# SDFM_SDFM_50268000h register map
Vendor: Texas Instruments
Peripheral module from a debugger description file (folder AM263P).
Registers are 16-bit, read-write, reset 0x0 unless marked. A register's access mark holds for its fields unless they carry their own. Offsets are as the file gives them; lines under a group give offsets from that group; [hi:lo] are bit positions; {n}, {i} and the like mark numbered series; 'fields as' and 'values as' point back to an identical list; <NAME> marks a mode.

## SDFM
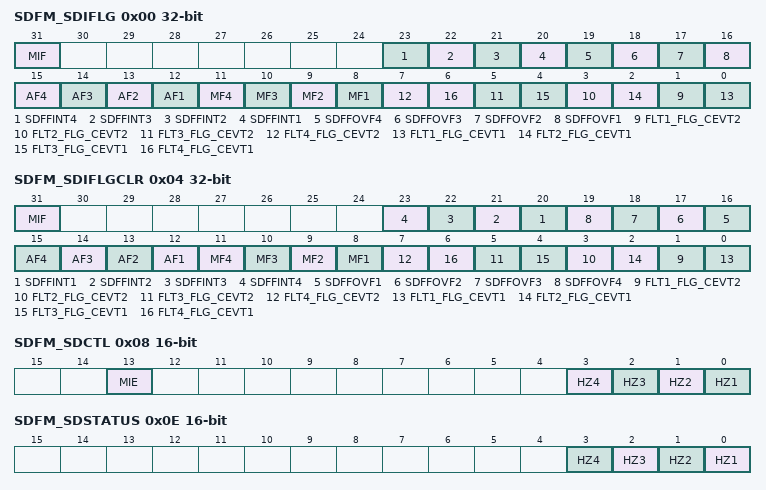
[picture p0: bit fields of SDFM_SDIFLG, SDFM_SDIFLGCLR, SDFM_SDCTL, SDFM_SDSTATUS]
0x00 SDFM_SDIFLG 32-bit ro — SD Interrupt Flag Register.
  [31] MIF — Set whenever any 'error' interrupt [MF1-4,IFL1-4,IFH1-4,SDFFOVF1-4] is active
  [23] SDFFINT4 — SDFIFO data ready interrupt for Ch4
  [22] SDFFINT3 — SDFIFO data ready interrupt for Ch3
  [21] SDFFINT2 — SDFIFO data ready interrupt for Ch2
  [20] SDFFINT1 — SDFIFO data ready interrupt for Ch1 0: SDFIFO data ready interrupt has NOT occurred 1: SDFIFO data ready interrupt has occurred
  [19] SDFFOVF4 — FIFO Overflow Flag for Ch4
  [18] SDFFOVF3 — FIFO Overflow Flag for Ch3
  [17] SDFFOVF2 — FIFO Overflow Flag for Ch2
  [16] SDFFOVF1 — FIFO Overflow Flag for Ch1 0 - FIFO has not overflowed 1 - FIFO overflowed. # words received in FIFO ' FIFO depth [16], NEW word is lost
  [n+11] AF{n} (n=1..4) — Acknowledge flag for Filter {n} 0:No new data available for Filter [in non-FIFO mode] 1:New data available for Filter [in non-FIFO mode]
  [n+7] MF{n} (n=1..4) — Modulator Failure for Filter {n} 0:Modulator is operating normally for Filter 1:Modulator failure for Filter
  [2n-1] FLT{n}_FLG_CEVT2 (n=1..4) — CEVT2 Interrupt flag for filter{n} 0:CEVT2 event has not occured 1:CEVT2 event has occurred
  [2n-2] FLT{n}_FLG_CEVT1 (n=1..4) — CEVT1 Interrupt flag for filter{n} 0:CEVT1 event has not occured 1:CEVT1 event has occurred
0x04 SDFM_SDIFLGCLR 32-bit access not given — SD Module Interrupt Flag Clear Bits: Writing a '1' will clear the respective flag bit in the SDIFLG register. Writes of '0' are ignored. Note: If user writes a '1' to clear a bit on the same cycle that the hardware is trying to set the bit to '1', then hardware has priority and the bit will not be cleared.
  [31] MIF — Flag-clear bit for SDFM Master Interrupt flag. Writing a 1 to clear MIF flag in SDIFLG register Writes of '0' are ignored. Note: If the MIF flag is cleared and other Interrupts are still pending, MIF will again be set to 1 on the following SysClk cycle, and the INT output will be reasserted [pulsed low] (access R/W1TS)
  [n+19] SDFFINT{n} (n=1..4) — SDFIFO data ready Interrupt flag-clear bit for Ch{n} (access R/W1TS)
  [n+15] SDFFOVF{n} (n=1..4) — SDFIFO overflow clear Ch{n} (access R/W1TS)
  [15] AF4 — Flag-clear bit for Acknowledge flag for Filter 4 (access R/W1TS)
  [14] AF3 — Flag Clear bit for AF3 (access R/W1TS)
  [13] AF2 — Flag Clear bit for AF2 (access R/W1TS)
  [12] AF1 — Flag Clear bit for AF1 (access R/W1TS)
  [n+7] MF{n} (n=1..4) — Flag Clear bit for MF{n} (access R/W1TS)
  [2n-1] FLT{n}_FLG_CEVT2 (n=1..4) — Flag Clear bit for FLT{n}_FLG_CEVT2 (access R/W1TS)
  [2n-2] FLT{n}_FLG_CEVT1 (n=1..4) — Flag Clear bit for FLT{n}_FLG_CEVT1 (access R/W1TS)
0x08 SDFM_SDCTL access not given — SD Control Register.
  [13] MIE rw — Master SDy_ERR interrupt enable 0:SDy_ERR Interrupt and interrupt flags are disabled 1:SDy_ERR Interrupt and interrupt flags are enabled
  [n-1] HZ{n} (n=1..4) — Flag Clear bit for HZ{n} (access R/W1TS)
0x0C SDFM_SDMFILEN — SD Master Filter Enable.
  [11] MFE — Master Filter Enable 0:All the four data filter units of SDFM module are disabled. All FIFOs are cleared 1:Data filter units can be enabled if bit FEN is '1'.
0x0E SDFM_SDSTATUS ro — SD Status Register.
  [n-1] HZ{n} (n=1..4) — High-level Threshold crossing [Z] flag Ch{n} Primarily intended for detecting 'zero'-crossing events. Unlike the primary comparator IFHx flag, it does not have the ability to generate an interrupt. 0:Comparator filter output ' SDCMPHZ{n}.HLTZ 1:Comparator filter output '= SDCMPHZ{n}.HLTZ
0x10 SDFM_SDINTMODE — SD Interrupt Mode register.
  [0] SDINTMODESEL — CompxH/L events interrupt mode select 0 CompxH/L events are treated as edge signals, rise-edge detect will be done to qualify the event for interrupt generation 1 CompxH/L events are treated as level signals. Rise-edge detect will not be performed and interrupt will be re-asserted if the event remains asserted.
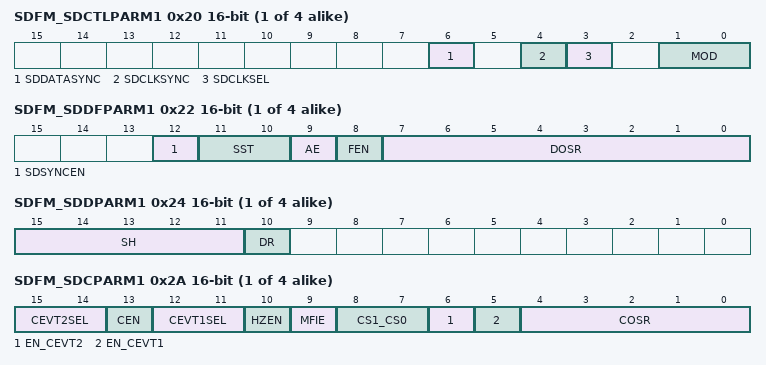
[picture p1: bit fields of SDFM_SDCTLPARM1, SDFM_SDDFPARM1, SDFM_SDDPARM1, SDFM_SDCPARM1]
{0x0+0x20*i} SDFM_SDCTLPARM{i} (i=1..4) — Control Parameter Register for Ch{i}.
  [6] SDDATASYNC — 0: SD Data is not passed through a synchronizer. 1:SD Data is passed through a synchronizer.
  [4] SDCLKSYNC — 0: SD Clock is not passed through a synchronizer. 1:SD Clock is passed through a synchronizer.
  [3] SDCLKSEL — SD{i} Clock source select. 0:Clock source to SDFM filter is its channel clock. 1:Clock source to SDFM filter is SD1 filter clock.
  [1:0] MOD — Modulator clock modes 0:Mode0:Modulator clock running at 1x data rate 1:Reserved 2:Reserved 3:Reserved
{0x2+0x20*i} SDFM_SDDFPARM{i} (i=1..4) — Data Filter Parameter Register for Ch{i}.
  [12] SDSYNCEN — PWM synchronization [SDSYNC] of data filter 0:PWM synchronization of data filter is disabled 1:PWM synchronization of data filter is enabled Note: SDSYNCx.SYNCSEL bits define which PWM signal is used to synchronize PWMs
  [11:10] SST — Data filter structure 00:Data filter runs with a Sincfast structure 01:Data filter runs with a Sinc1 structure 10:Data filter runs with a Sinc2 structure 11:Data filter runs with a Sinc3 structure
  [9] AE — Data filter Acknowledge Enable 0:Acknowledge flag is disabled for the particular filter 1:Acknowledge flag is enabled for the particular filter
  [8] FEN — Filter Enable 0: The data filter is disabled and no data is produced 1: The data filter is enabled and data are produced in the data filter Note: When filter is disabled, DOSR counter held in reset, filter data erased. Also resets FIFO pointers and clears the FIFO
  [7:0] DOSR — Data filter Oversampling ratio The actual oversampling ratio of data filter is DOSR + 1 These bits set the oversampling ratio of the data filter. 0x0FF represents an oversampling ratio of 256.
{0x4+0x20*i} SDFM_SDDPARM{i} (i=1..4) — Data Parameter Register for Ch{i}.
  [15:11] SH — Shift Control These bits indicate by how many bits the 16-bit window is shifted up when 16-bit data representation is chosen.
  [10] DR — Data filter Data representation 0:Data stored in16b2's complement 1:Data stored in32b2's complement
{0x6+0x20*i} SDFM_SDFLT{i}CMPH1 reset 0x7FFF (i=1..4) — High-level Threshold Register for Ch{i}.
  [14:0] HLT — Unsigned high-level threshold for the comparator filter output.
{0x8+0x20*i} SDFM_SDFLT{i}CMPL1 (i=1..4) — Low-level Threshold Register for Ch{i}.
  [14:0] LLT — Unsigned low-level threshold for the comparator filter output.
{0xA+0x20*i} SDFM_SDCPARM{i} (i=1..4) — Comparator Filter Parameter Register for Ch{i}.
  [15:14] CEVT2SEL — Comparator Event2 Select 00: COMPL1 01:COMPL1 OR COMPH1 10:COMPL2 11:COMPL2 OR COMPH2
  [13] CEN — Comparator Filter enable 0:Disable comparator filter 1:Enable comparator filter
  [12:11] CEVT1SEL — Comparator Event1 Select 00: COMPH1 01:COMPL1 OR COMPH1 10:COMPH2 11:COMPL2 OR COMPH2
  [10] HZEN — High level [Z] Threshold crossing output enable 0:Disable Higher level Threshold [Z] crossing 1:Enable Higher level Threhold [Z] crossing
  [9] MFIE — Modulator Failure Interrupt Enable 0:Disable modulator failure interrupt and its flag 1:Enable modulator failure interrupt and its flag
  [8:7] CS1_CS0 — Comparator filter structure 00:Comparator filter runs with a sincfast structure 01:Comparator filter runs with a Sinc1 structure 10:Comparator filter runs with a Sinc2 structure 11:Comparator filter runs with a Sinc3 structure
  [6] EN_CEVT2 — CEVT2 interrupt enable 0:Disable CEVT2 interrupt 1:Enable CEVT2 interrupt
  [5] EN_CEVT1 — CEVT1 interrupt enable 0:Disable CEVT1 interrupt 1:Enable CEVT1 interrupt
  [4:0] COSR — Comparator Oversampling ratio. The actual rate is COSR + 1. These bits set the oversampling ratio of the filter. 0x1F represents an oversampling ratio of 32
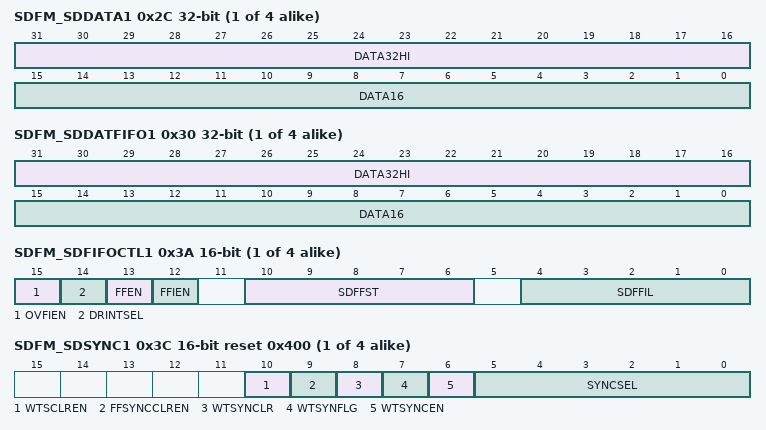
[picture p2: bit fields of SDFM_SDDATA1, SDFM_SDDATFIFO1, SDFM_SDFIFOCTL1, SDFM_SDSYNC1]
{0xC+0x20*i} SDFM_SDDATA{i} 32-bit ro (i=1..4) — Data Filter Data Register (16 or 32bit) for Ch{i}.
  [31:16] DATA32HI — Hi-order16bin32bmode, 16-bit Data in16bmode
  [15:0] DATA16 — Lo-order16bin32bmode
{0x10+0x20*i} SDFM_SDDATFIFO{i} 32-bit ro (i=1..4) — Filter Data FIFO Output(32b) for Ch{i}.
  fields as SDFM_SDDATA1
{0x14+0x20*i} SDFM_SDCDATA{i} ro (i=1..4) — Comparator Filter Data Register (16b) for Ch{i}.
  [15:0] DATA16 — Comparator Data output -16bonly
{0x16+0x20*i} SDFM_SDFLT{i}CMPH2 reset 0x7FFF (i=1..4) — Second high level threhold for CH{i}.
  [14:0] HLT2 — Second Unsigned high-level threshold for the comparator filter output.
{0x18+0x20*i} SDFM_SDFLT{i}CMPHZ (i=1..4) — High-level (Z) Threshold Register for Ch{i}.
  [14:0] HLTZ — Unsigned High-level threshold [Z] for the comparator filter output Primarily intended for detecting 'zero'-crossing events. Unlike the primary comparator SDCMPHx, it does not have the ability to generate an interrupt.
{0x1A+0x20*i} SDFM_SDFIFOCTL{i} access per field (i=1..4) — FIFO Control Register for Ch{i}.
  [15] OVFIEN rw — SDFIFO Overflow interrupt enable 0:SDFIFO Overflow condition will not generate an interrupt 1:SDFIFO overflow condition generates an interrupt on SDy_ERR
  [14] DRINTSEL rw — Data-Ready Interrupt [DRINT] source select 0 = AF1 [Select non-FIFO data-ready interrupt] 1 = SDFFINT1 [Select FIFO data-ready interrupt]
  [13] FFEN rw — SDFIFO Enable 0: Disable FIFO operation 1: Enable FIFO operation Note: When FIFO is disabled, FIFO contents are cleared
  [12] FFIEN rw — SDFIFO data ready Interrupt Enable
  [10:6] SDFFST ro — SDFIFO Status 00000 FIFO empty 00001 FIFO has 1 word . . . . 10000 FIFO has 16 words
  [4:0] SDFFIL rw — SDFIFO interrupt level bits The FIFO will generate an interrupt when the FIFO status [SDFFST] '= FIFO level [SDFFIL ]
{0x1C+0x20*i} SDFM_SDSYNC{i} access per field reset 0x400 (i=1..4) — SD Filter Sync control for Ch{i}.
  [10] WTSCLREN rw — WTSYNFLG Clear-on-FIFOINT Enable 0:WTSYNFLG can only be cleared manually [using WTSYNCLR bit] 1:WTSYNFLG is cleared automatically on SDFFINT
  [9] FFSYNCCLREN rw — FIFO Clear-on-SDSYNC Enable 0:SDFIFO is not automaticaly cleared upon receiving SDSYNC 1:SDFIFO is automaticaly cleared upon receiving SDSYNC
  [8] WTSYNCLR rw — Wait-for-Sync Flag Clear [always reads 0] 0:Write of 0 has no effect 1:Write of 1 clears WTSYNFLG
  [7] WTSYNFLG ro — Wait-for-Sync Flag 0:SDSYNC event has not occurred 1:SDSYNC event occurred.
  [6] WTSYNCEN rw — Wait-for-Sync Enable 0:Incoming Data written to SDFIFO on every Data-Ready [DR] Event 1:Incoming Data written to SDFIFO on DR event only after SDSYNC event occurs
  [5:0] SYNCSEL rw — Defines source for the SDSYNC Input on this channel Refer SDSYNCx.SYNCSEL table
{0x1E+0x20*i} SDFM_SDFLT{i}CMPL2 (i=1..4) — Second low level threhold for CH{i}.
  [14:0] LLT2 — Second Unsigned low-level threshold for the comparator filter output.
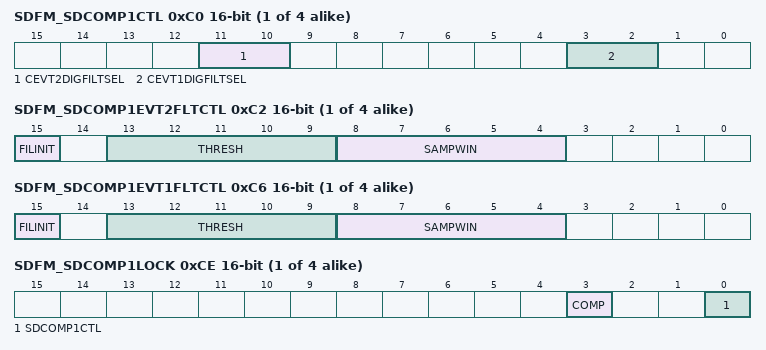
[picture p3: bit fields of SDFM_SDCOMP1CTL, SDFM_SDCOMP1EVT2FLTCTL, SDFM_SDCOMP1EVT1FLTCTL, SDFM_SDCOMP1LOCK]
{0xB0+0x10*i} SDFM_SDCOMP{i}CTL (i=1..4) — SD Comparator event filter{i} Control Register.
  [11:10] CEVT2DIGFILTSEL — High comparator COMPH source select. 0 CEVT2 output drives COMPLOUT 1 Reserved 2 Output of digital filter drives COMPLOUT 3 Reserved
  [3:2] CEVT1DIGFILTSEL — High comparator COMPH source select. 0 CEVT1 output drives COMPHOUT 1 Reserved 2 Output of digital filter drives COMPHOUT 3 Reserved
{0xB2+0x10*i} SDFM_SDCOMP{i}EVT2FLTCTL access not given (i=1..4) — COMPL/CEVT2 Digital filter{i} Control Register.
  [15] FILINIT — Low filter initialization. 0 No effect 1 Initialize all samples to the filter input value (access R/W1TS)
  [13:9] THRESH rw — Low filter majority voting threshold. At least THRESH samples of the opposite state must appear within the sample window in order for the output to change state.
  [8:4] SAMPWIN rw — Low filter sample window size. Number of samples to monitor is SAMPWIN+1.
{0xB4+0x10*i} SDFM_SDCOMP{i}EVT2FLTCLKCTL (i=1..4) — COMPL/CEVT2 Digital filter{i} Clock Control Register.
  [9:0] CLKPRESCALE — Low filter sample clock prescale. Number of system clocks between samples.
{0xB6+0x10*i} SDFM_SDCOMP{i}EVT1FLTCTL access not given (i=1..4) — COMPH/CEVT1 Digital filter{i} Control Register.
  [15] FILINIT — High filter initialization. 0 No effect 1 Initialize all samples to the filter input value (access R/W1TS)
  [13:9] THRESH rw — High filter majority voting threshold. At least THRESH samples of the opposite state must appear within the sample window in order for the output to change state.
  [8:4] SAMPWIN rw — High filter sample window size. Number of samples to monitor is SAMPWIN+1.
{0xB8+0x10*i} SDFM_SDCOMP{i}EVT1FLTCLKCTL (i=1..4) — COMPH/CEVT1 Digital filter{i} Clock Control Register.
  [9:0] CLKPRESCALE — High filter sample clock prescale. Number of system clocks between samples.
{0xBE+0x10*i} SDFM_SDCOMP{i}LOCK access not given (i=1..4) — SD compartor event filter{i} Lock Register.
  [3] COMP — Lock write-access to the SDCOMP{i}EVT1/2FLTTCTL and COMP{i}FILCLKCTL registers. 0 SDCOMP{i}EVT1/2FLTCTL and SDCOMP{i}EVT1/2FLTCLKCTL registers are not locked. Write 0 to this bit has no effect. 1 SDCOMP{i}EVT1/2FLTCTL and SDCOMP{i}EVT1/2FLTCLKCTL registers are locked. Only a system reset can clear this bit. (access R/W1TS)
  [0] SDCOMP{i}CTL — Lock write-access to the SDCOMP{i}CTL register. 0 SDCOMP{i}CTL register is not locked. Write 0 to this bit has no effect. 1 SDCOMP{i}CTL register is locked. Only a system reset can clear this bit. (access R/W1TS)
